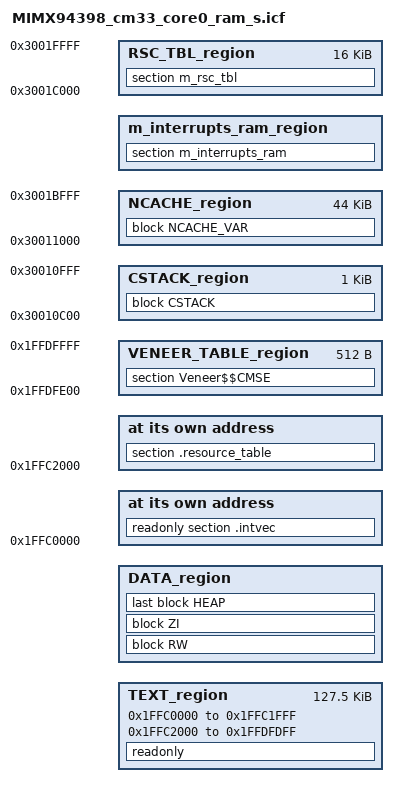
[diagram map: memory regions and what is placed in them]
/*
** ###################################################################
**     Processors:          MIMX94398AVKE_cm33_core0
**                          MIMX94398AVKJ_cm33_core0
**                          MIMX94398AVKM_cm33_core0
**                          MIMX94398AVME_cm33_core0
**                          MIMX94398AVMJ_cm33_core0
**                          MIMX94398AVMM_cm33_core0
**                          MIMX94398CVKE_cm33_core0
**                          MIMX94398CVKJ_cm33_core0
**                          MIMX94398CVKM_cm33_core0
**                          MIMX94398CVME_cm33_core0
**                          MIMX94398CVMJ_cm33_core0
**                          MIMX94398CVMM_cm33_core0
**                          MIMX94398DVKE_cm33_core0
**                          MIMX94398DVKJ_cm33_core0
**                          MIMX94398DVKM_cm33_core0
**                          MIMX94398DVME_cm33_core0
**                          MIMX94398DVMJ_cm33_core0
**                          MIMX94398DVMM_cm33_core0
**                          MIMX94398XVKE_cm33_core0
**                          MIMX94398XVKJ_cm33_core0
**                          MIMX94398XVKM_cm33_core0
**                          MIMX94398XVME_cm33_core0
**                          MIMX94398XVMJ_cm33_core0
**                          MIMX94398XVMM_cm33_core0
**
**     Compiler:            IAR ANSI C/C++ Compiler for ARM
**     Reference manual:    iMX943RM rev1 draftK
**     Version:             rev. 1.0, 2023-11-01
**     Build:               b241111
**
**     Abstract:
**         Linker file for the IAR ANSI C/C++ Compiler for ARM
**
**     Copyright 2016 Freescale Semiconductor, Inc.
**     Copyright 2016-2024 NXP
**     SPDX-License-Identifier: BSD-3-Clause
**
**     http:                 www.nxp.com
**     mail:                 support@nxp.com
**
** ###################################################################
*/


define symbol __ram_vector_table_size__ =  isdefinedsymbol(__ram_vector_table__) ? 0x00002000 : 0;
define symbol __ram_vector_table_offset__ =  isdefinedsymbol(__ram_vector_table__) ? 0x00001FFF : 0;

define symbol m_interrupts_start       = 0x1FFC0000;
define symbol m_interrupts_end         = 0x1FFC1FFF;

define symbol m_text_start             = 0x1FFC2000;
define symbol m_text_end               = 0x1FFDFDFF;

/* 512B - memory for veneer table (NSC - secure, non-secure callable memory) */
define symbol m_veneer_table_start     = 0x1FFDFE00;
define symbol m_veneer_table_end       = 0x1FFDFFFF;


define symbol m_interrupts_ram_start   = 0x30003000;
define symbol m_interrupts_ram_end     = 0x30003000 + __ram_vector_table_offset__;

define symbol m_data_start             = m_interrupts_ram_start + __ram_vector_table_size__;
define symbol m_data_end               = 0x30010FFF;

define symbol m_ncache_start          = 0x30011000;
define symbol m_ncache_end            = 0x3001BFFF;

define symbol m_rsc_tbl_start          = 0x3001C000;
define symbol m_rsc_tbl_end            = 0x3001FFFF;

/* Sizes */
if (isdefinedsymbol(__stack_size__)) {
  define symbol __size_cstack__        = __stack_size__;
} else {
  define symbol __size_cstack__        = 0x0400;
}

if (isdefinedsymbol(__heap_size__)) {
  define symbol __size_heap__          = __heap_size__;
} else {
  define symbol __size_heap__          = 0x0400;
}

define exported symbol __NCACHE_REGION_START   = m_ncache_start;
define exported symbol __NCACHE_REGION_SIZE    = m_ncache_end - m_ncache_start + 1;

define exported symbol __VECTOR_TABLE  = m_interrupts_start;
define exported symbol __VECTOR_RAM    = isdefinedsymbol(__ram_vector_table__) ? m_interrupts_ram_start : m_interrupts_start;
define exported symbol __RAM_VECTOR_TABLE_SIZE = __ram_vector_table_size__;

define memory mem with size = 4G;
define region TEXT_region = mem:[from m_interrupts_start to m_interrupts_end]
                          | mem:[from m_text_start to m_text_end];
define region DATA_region = mem:[from m_data_start to m_data_end-__size_cstack__];
define region RSC_TBL_region = mem:[from m_rsc_tbl_start to m_rsc_tbl_end];
define region CSTACK_region = mem:[from m_data_end-__size_cstack__+1 to m_data_end];
define region NCACHE_region = mem:[from m_ncache_start to m_ncache_end];
define region m_interrupts_ram_region = mem:[from m_interrupts_ram_start to m_interrupts_ram_end];
define region VENEER_TABLE_region = mem:[from m_veneer_table_start to m_veneer_table_end];

define block CSTACK    with alignment = 8, size = __size_cstack__   { };
define block HEAP      with alignment = 8, size = __size_heap__     { };
define block RW        { readwrite };
define block ZI        { zi };
define block NCACHE_VAR    { section NonCacheable , section NonCacheable.init };

initialize by copy { readwrite, section .textrw };
do not initialize  { section .noinit };

keep{section .resource_table};

place at address mem: m_interrupts_start    { readonly section .intvec };
".resource_table": place at address mem: m_text_start {section .resource_table};
place in TEXT_region                        { readonly };
place in DATA_region                        { block RW };
place in DATA_region                        { block ZI };
place in DATA_region                        { last block HEAP };
place in CSTACK_region                      { block CSTACK };
place in RSC_TBL_region                     { section m_rsc_tbl };
place in m_interrupts_ram_region            { section m_interrupts_ram };
place in VENEER_TABLE_region                { section Veneer$$CMSE };
place in NCACHE_region                      { block NCACHE_VAR };
